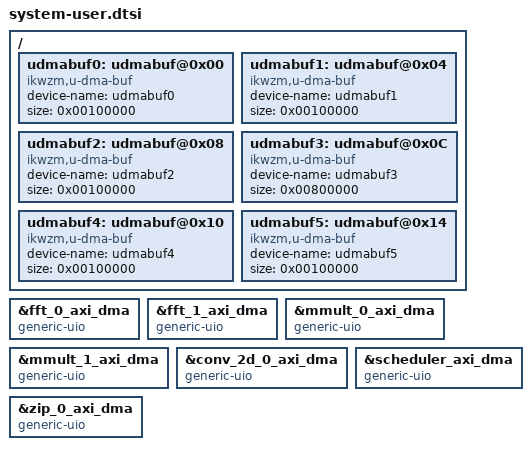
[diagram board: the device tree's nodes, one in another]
/include/ "system-conf.dtsi"
/ {
    udmabuf0: udmabuf@0x00 {
        compatible = "ikwzm,u-dma-buf";
        device-name = "udmabuf0";
        // 1 MiB = 1048576 B = 0x100000
        size = <0x00100000>;
    };
    udmabuf1: udmabuf@0x04 {
        compatible = "ikwzm,u-dma-buf";
        device-name = "udmabuf1";
        // 1 MiB = 1048576 B = 0x100000
        size = <0x00100000>;
    };
    udmabuf2: udmabuf@0x08 {
        compatible = "ikwzm,u-dma-buf";
        device-name = "udmabuf2";
        // 1 MiB = 1048576 B = 0x100000
        size = <0x00100000>;
    };
    udmabuf3: udmabuf@0x0C {
        compatible = "ikwzm,u-dma-buf";
        device-name = "udmabuf3";
        // 1 MiB = 1048576 B = 0x100000
        size = <0x00800000>;
    };
    udmabuf4: udmabuf@0x10 {
        compatible = "ikwzm,u-dma-buf";
        device-name = "udmabuf4";
        // 1 MiB = 1048576 B = 0x100000
        size = <0x00100000>;
    };
    udmabuf5: udmabuf@0x14 {
        compatible = "ikwzm,u-dma-buf";
        device-name = "udmabuf5";
        // 1 MiB = 1048576 B = 0x100000
        size = <0x00100000>;
    };
};
&fft_0_axi_dma {
    compatible = "generic-uio";
};
&fft_1_axi_dma {
    compatible = "generic-uio";
};
&mmult_0_axi_dma {
    compatible = "generic-uio";
};
&mmult_1_axi_dma {
    compatible = "generic-uio";
};
&conv_2d_0_axi_dma {
    compatible = "generic-uio";
};
&scheduler_axi_dma {
    compatible = "generic-uio";
};
&zip_0_axi_dma {
    compatible = "generic-uio";
};
